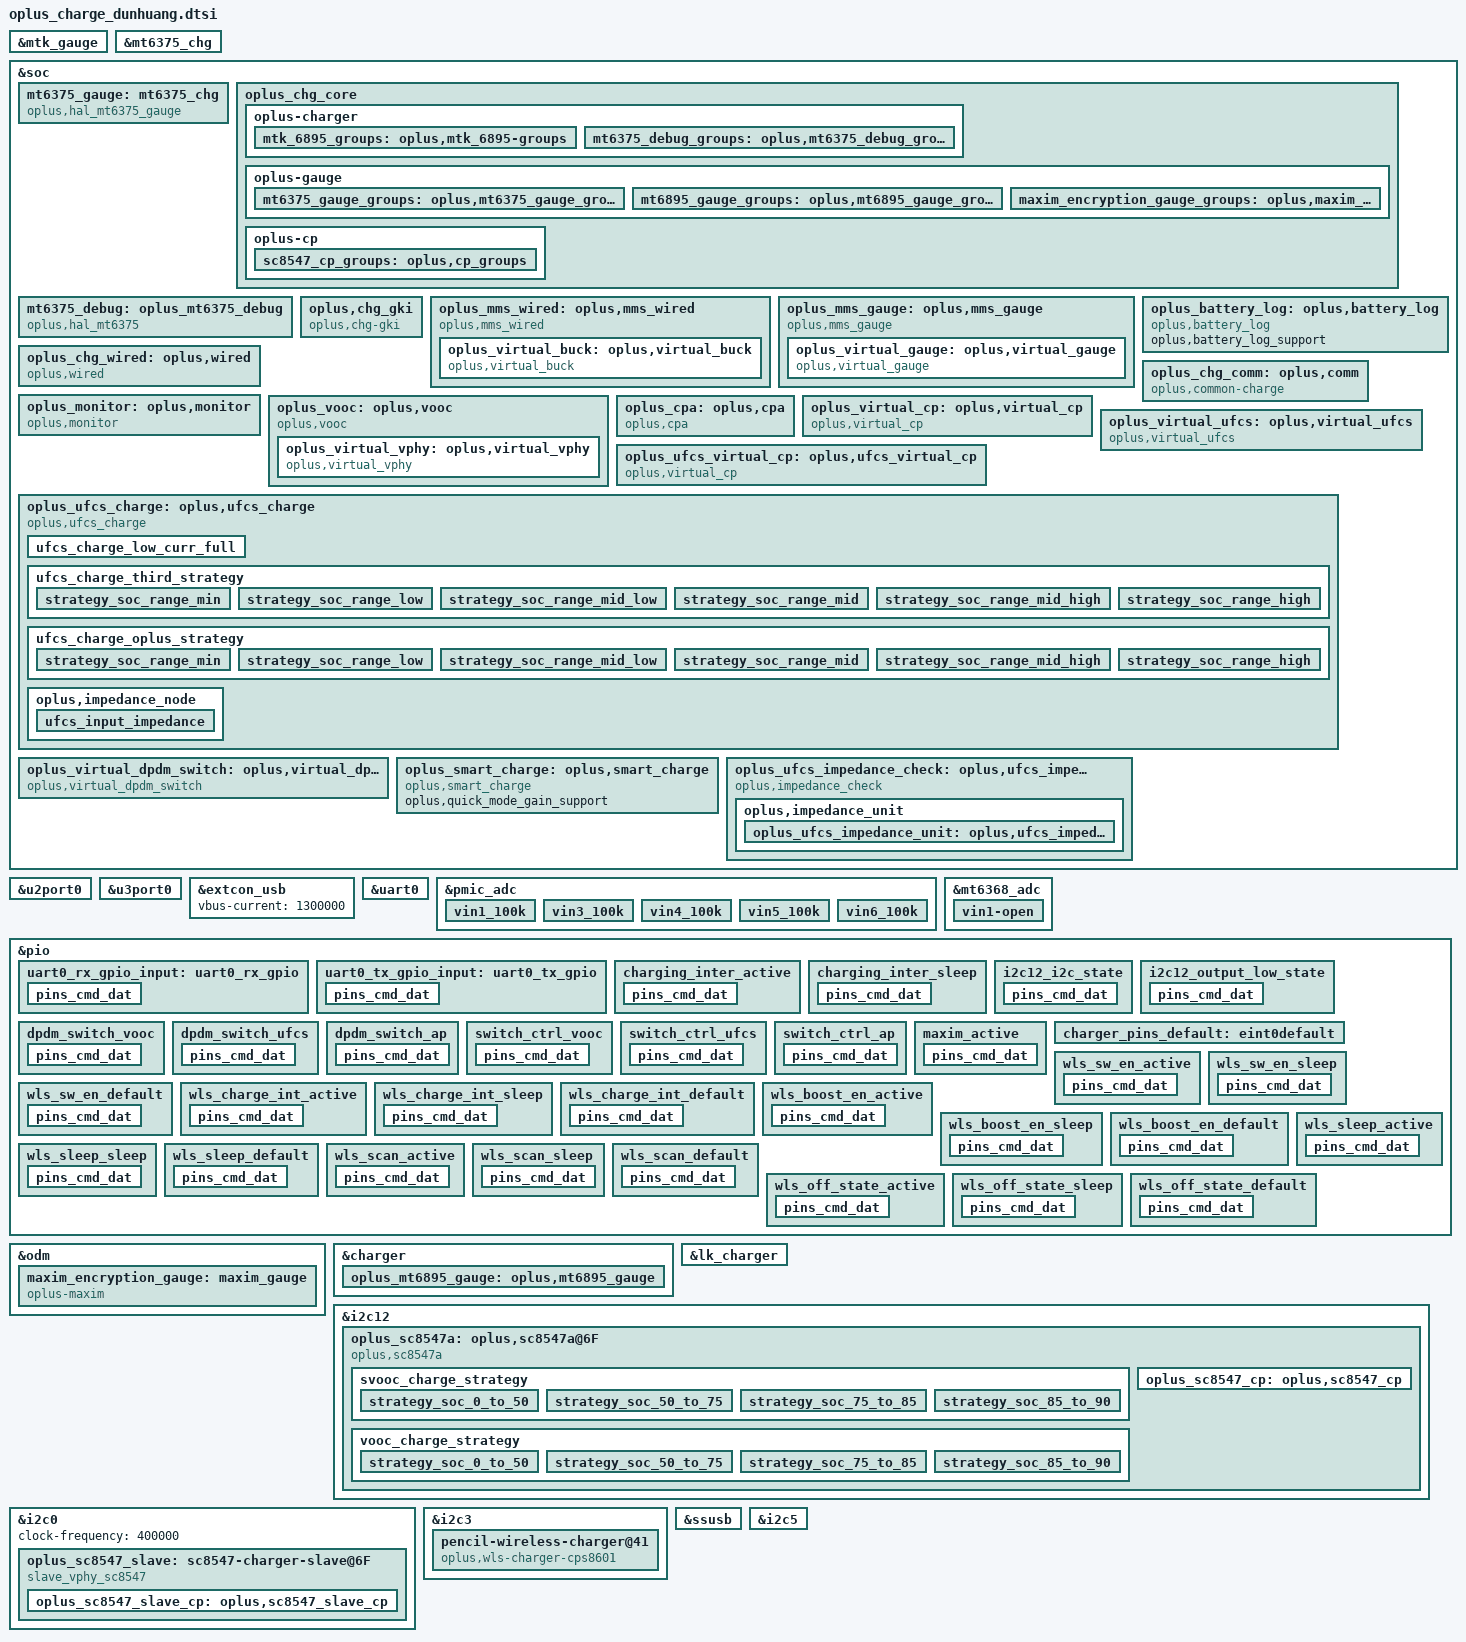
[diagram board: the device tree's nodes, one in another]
// SPDX-License-Identifier: GPL-2.0-only
/*
* Copyright (C) 2021-2020 Oplus. All rights reserved.
*/
#include <dt-bindings/iio/mt635x-auxadc.h>
#include <dt-bindings/iio/adc/mediatek,mt6375_auxadc.h>
#include <dt-bindings/pinctrl/mt6373-pinfunc.h>
#include <dt-bindings/pinctrl/mt65xx.h>
//#include "oplus_charge_22113.h"
#include "oplus_chg.h"

/*
 *
 * CPU:MT8792 dunhuang
 *
 * UTXD0 -->GPIO207
 * URXD0 -->GPIO208
 *
 * I2C
 * MASTER_CHG --> I2C5 MT6375
 * CP_MASTER  --> I2C12 SC8547B
 * CP_SLAVE   --> I2C0 SC8547B
 *
 * IRQB
 * EINT_CHG_1 (cp1 irq)               -->GPIO40
 * EINT_CHG_2 (cp2 irq)               -->GPIO61
 *
 * GPIO
 * VBUS_SHORT(防烧口)                 --> GPIO76
 * USB_SWITCH_1(usb/uart&vooc switch) --> GPIO115
 * USB_SWITCH_2(uart/vooc switch)     --> GPIO134
 * SEC_IC (加密电池GPIO for 80W)      --> GPIO23
 *
 * ADC:
 * MT6363 AUXADC_VIN6 				--> VBAT_BTB (Battery BTB)
 * MT6363 AUXADC_VIN1               --> NTC_USBCON_TEM (USB BTB)
 *
 * 
 * MT6368 AUXADC_VIN1				--> BATThermal_1 Ð¡°åNTC
 * MT6363 AUXADC_VIN3				--> ADC3 H10 //BB_USB_ADC1 防烧口NTC1
 * MT6363 AUXADC_VIN4				--> ADC4 G9//BB_USB_ADC2 防烧口NTC2
 * MT6363 AUXADC_VIN5				--> ADC5 H9//NTC_CHARGE (充电IC旁)
 *
 */

//&mtk_gauge {
//	disable-mtkbattery = <(1)>;
//	charger = <&mt6375_chg>;
//};

/* charge start */

&mtk_gauge {
	status = "okay";
	charger = <&mt6375_chg>;
	FUELGAGUE_APPLY = <(1)>;
	IS_SUBBOARD_TEMP_SUPPORT = <(0)>;
	EXTERNAL_AUTHENTICATE =<(1)>;
	Enable_Is_Force_Full = <(1)>;
	active-table = <(5)>;
	r-fg-value = <(2)>;/* R_sense resistance. 2 milliohm */
	com-r-fg-value = <(0)>;/* R_sense compensate resistance. not use COM_R_FG_VALUE */
	UNIT_MULTIPLE = <(1)>;
	RBAT_PULL_DOWN_R = <(24000)>;
	RBAT_PULL_UP_R = <(12000)>;
	RBAT_PULL_UP_VOLT = <(1840)>;
	USE_MORE_PRECISE_NTC_TABLE = <(1)>;
	car-tune-value = <(98)>;
	KEEP_100_PERCENT = <(0)>;
	temperature-t4 = <(-10)>;
	/* Battery temperature T4 */

	io-channels = <&mt6375_auxadc MT6375_AUXADC_BATSNS>,
				  <&mt6375_auxadc MT6375_AUXADC_BATON>,
				  <&mt6375_auxadc MT6375_AUXADC_IMP>,
				  <&mt6375_auxadc MT6375_AUXADC_IMIX_R>,
				  <&mt6375_auxadc MT6375_AUXADC_VREF>,
				  <&pmic_adc AUXADC_VIN2>;
	io-channel-names = "bat_volt", "bat_temp", "ptim_bat_volt",
					   "ptim_r", "vref", "auxadc5-batt_id_v";

	#include "bat_setting/mt6897_battery_prop_dim2_ext_dunhuang.dtsi"
	#include "bat_setting/mt6897_battery_table_dunhuang.dtsi"
};

&mt6375_chg {
	ircmp_v = <0>;
	chg-tmr = <20>;
};

&soc {
	mt6375_gauge: mt6375_chg {
		status = "okay";
		compatible = "oplus,hal_mt6375_gauge";

		oplus,ic_type = <OPLUS_CHG_IC_GAUGE>;
		oplus,ic_index = <0>;
		oplus,batt_num = <1>;
		oplus,mtk_gauge_power_sel_support;
	};
};

&u2port0 {
	mediatek,eye-vrt = <7>;
	mediatek,eye-term = <7>;
	mediatek,rev6 = <3>;
	mediatek,eye-vrt-host = <7>;
	mediatek,eye-term-host = <7>;
	mediatek,rev6-host = <3>;
	mediatek,discth = <0x9>;
};

&u3port0 {
	mediatek,tx-lctxc0 = <34>;
	mediatek,tx-lctxcp1 = <14>;
};

&extcon_usb {
	vbus-current = <1300000>;
};

&uart0 {
	pinctrl-names = "uart0_rx_gpio", "uart0_tx_gpio";
	pinctrl-0 = <&uart0_rx_gpio_input>;
	pinctrl-1 = <&uart0_tx_gpio_input>;
	status = "okay";

	txpin = <207>;
	rxpin = <208>;
};


/* pmic_adc is defined in mt6363.dtsi */
&pmic_adc {
	vin1_100k {
		channel = <AUXADC_VIN1>;
		pures = <ADC_PURES_100K>;
	};
	vin3_100k {
		channel = <AUXADC_VIN3>;
		pures = <ADC_PURES_100K>;
	};
	vin4_100k {
		channel = <AUXADC_VIN4>;
		pures = <ADC_PURES_100K>;
	};
	vin5_100k {
		channel = <AUXADC_VIN5>;
		pures = <ADC_PURES_100K>;
	};
	vin6_100k {
		channel = <AUXADC_VIN6>;
		pures = <ADC_PURES_100K>;
	};
};

/* mt6368_adc is defined in mt6368.dtsi */
&mt6368_adc {
	vin1-open {
		channel = <AUXADC_VIN1>;
		pures = <ADC_PURES_OPEN>;
	};
};

&pio {
	uart0_rx_gpio_input: uart0_rx_gpio {
		pins_cmd_dat {
			pinmux = <PINMUX_GPIO208__FUNC_GPIO208>; /* URXD0 */
			input-enable;
			bias-disable;
		};
	};

	uart0_tx_gpio_input: uart0_tx_gpio {
		pins_cmd_dat {
			pinmux = <PINMUX_GPIO207__FUNC_GPIO207>; /* UTXD0 */
			input-enable;
			bias-disable;
		};
	};

	charging_inter_active: charging_inter_active {
		pins_cmd_dat {
			pinmux = <PINMUX_GPIO40__FUNC_GPIO40>;
			input-enable;
			bias-pull-up;
		};
	};

	charging_inter_sleep: charging_inter_sleep {
		pins_cmd_dat {
			pinmux = <PINMUX_GPIO40__FUNC_GPIO40>;
			input-enable;
			bias-pull-up;
		};
	};

	i2c12_i2c_state: i2c12_i2c_state {
		pins_cmd_dat {
			pinmux = <PINMUX_GPIO162__FUNC_SDA12>,
				 <PINMUX_GPIO161__FUNC_SCL12>;
			bias-disable;
		};
	};

	i2c12_output_low_state: i2c12_output_low_state {
		pins_cmd_dat {
			pinmux = <PINMUX_GPIO162__FUNC_GPIO162>,
				 <PINMUX_GPIO161__FUNC_GPIO161>;
			output-low;
		};
	};

	dpdm_switch_vooc: dpdm_switch_vooc {
		pins_cmd_dat {
			pinmux = <PINMUX_GPIO115__FUNC_GPIO115>;
			output-high;
		};
 	};

 	dpdm_switch_ufcs: dpdm_switch_ufcs {
 		pins_cmd_dat {
			pinmux = <PINMUX_GPIO115__FUNC_GPIO115>;
			output-high;
		};
 	};

 	dpdm_switch_ap: dpdm_switch_ap {
 		pins_cmd_dat {
			pinmux = <PINMUX_GPIO115__FUNC_GPIO115>;
			output-low;
		};
 	};

 	switch_ctrl_vooc: switch_ctrl_vooc {
 		pins_cmd_dat {
			pinmux = <PINMUX_GPIO134__FUNC_GPIO134>;
			output-high;
		};
 	};

 	switch_ctrl_ufcs: switch_ctrl_ufcs {
 		pins_cmd_dat {
			pinmux = <PINMUX_GPIO134__FUNC_GPIO134>;
			output-high;
		};
 	};

 	switch_ctrl_ap: switch_ctrl_ap {
 		pins_cmd_dat {
			pinmux = <PINMUX_GPIO134__FUNC_GPIO134>;
			output-low;
		};
 	};

	maxim_active: maxim_active {
		pins_cmd_dat {
			pinmux = <PINMUX_GPIO23__FUNC_GPIO23>;
			drive-strength = <6>;
			bias-pull-up;
		};
	};

	charger_pins_default: eint0default {
	};

};


&soc {
	oplus_chg_core {
		oplus,chg_framework_v2;
		oplus,smart_charging_screenoff;
		oplus,common-charge-icl-support;

		oplus-charger {
			mtk_6895_groups: oplus,mtk_6895-groups {
				functions = <
					OPLUS_IC_FUNC_INIT
					OPLUS_IC_FUNC_EXIT
					OPLUS_IC_FUNC_REG_DUMP
					OPLUS_IC_FUNC_SMT_TEST
					OPLUS_IC_FUNC_BUCK_INPUT_PRESENT
					OPLUS_IC_FUNC_BUCK_INPUT_SUSPEND
					OPLUS_IC_FUNC_BUCK_INPUT_IS_SUSPEND
					OPLUS_IC_FUNC_BUCK_OUTPUT_SUSPEND
					OPLUS_IC_FUNC_BUCK_OUTPUT_IS_SUSPEND
					OPLUS_IC_FUNC_BUCK_SET_ICL
					OPLUS_IC_FUNC_BUCK_GET_ICL
					OPLUS_IC_FUNC_BUCK_SET_FCC
					OPLUS_IC_FUNC_BUCK_SET_FV
					OPLUS_IC_FUNC_BUCK_SET_ITERM
					OPLUS_IC_FUNC_BUCK_GET_INPUT_CURR
					OPLUS_IC_FUNC_BUCK_GET_INPUT_VOL
					OPLUS_IC_FUNC_OTG_BOOST_ENABLE
					OPLUS_IC_FUNC_BUCK_GET_CC_ORIENTATION
					OPLUS_IC_FUNC_BUCK_GET_CHARGER_TYPE
					OPLUS_IC_FUNC_BUCK_RERUN_BC12
					OPLUS_IC_FUNC_BUCK_QC_DETECT_ENABLE
					OPLUS_IC_FUNC_BUCK_SET_QC_CONFIG
					OPLUS_IC_FUNC_BUCK_SET_PD_CONFIG
					OPLUS_IC_FUNC_GET_SHUTDOWN_SOC
					OPLUS_IC_FUNC_BACKUP_SOC
					OPLUS_IC_FUNC_GET_TYPEC_MODE
					OPLUS_IC_FUNC_SET_TYPEC_MODE
					OPLUS_IC_FUNC_GET_TYPEC_ROLE
					OPLUS_IC_FUNC_GET_OTG_ENABLE
					OPLUS_IC_FUNC_BUCK_GET_HW_DETECT
					OPLUS_IC_FUNC_SET_USB_DISCHG_ENABLE
					OPLUS_IC_FUNC_GET_USB_DISCHG_STATUS
					OPLUS_IC_FUNC_IS_OPLUS_SVID
					OPLUS_IC_FUNC_BUCK_GET_USB_BTB_TEMP
					OPLUS_IC_FUNC_BUCK_GET_BATT_BTB_TEMP
					OPLUS_IC_FUNC_BUCK_SHIPMODE_ENABLE
					OPLUS_IC_FUNC_BUCK_SET_AICL_POINT
					OPLUS_IC_FUNC_SET_OTG_BOOST_CURR_LIMIT
					OPLUS_IC_FUNC_BUCK_GET_FV
					OPLUS_IC_FUNC_BUCK_GET_TYPEC_STATE
				>;
				virqs = <
					OPLUS_IC_VIRQ_ERR
					OPLUS_IC_VIRQ_CC_DETECT
					OPLUS_IC_VIRQ_PLUGIN
					OPLUS_IC_VIRQ_CC_CHANGED
					OPLUS_IC_VIRQ_CHG_TYPE_CHANGE
					OPLUS_IC_VIRQ_OTG_ENABLE
					OPLUS_IC_VIRQ_SVID
					OPLUS_IC_VIRQ_TYPEC_STATE
				>;
			};


			mt6375_debug_groups: oplus,mt6375_debug_groups {
				functions = <
					OPLUS_IC_FUNC_INIT
					OPLUS_IC_FUNC_EXIT
				>;
				virqs = <
					OPLUS_IC_VIRQ_ERR
				>;
			};
		};

		oplus-gauge {
			mt6375_gauge_groups: oplus,mt6375_gauge_groups {
				functions = <
					OPLUS_IC_FUNC_INIT
					OPLUS_IC_FUNC_EXIT
					OPLUS_IC_FUNC_REG_DUMP
					OPLUS_IC_FUNC_SMT_TEST
					OPLUS_IC_FUNC_GAUGE_GET_BATT_VOL
					OPLUS_IC_FUNC_GAUGE_GET_BATT_MAX
					OPLUS_IC_FUNC_GAUGE_GET_BATT_MIN
					OPLUS_IC_FUNC_GAUGE_GET_BATT_CURR
					OPLUS_IC_FUNC_GAUGE_GET_BATT_TEMP
					OPLUS_IC_FUNC_GAUGE_GET_BATT_SOC
					OPLUS_IC_FUNC_GAUGE_GET_BATT_FCC
					OPLUS_IC_FUNC_GAUGE_GET_BATT_CC
					OPLUS_IC_FUNC_GAUGE_GET_BATT_RM
					OPLUS_IC_FUNC_GAUGE_GET_BATT_SOH
					OPLUS_IC_FUNC_GAUGE_GET_BATT_HMAC
					OPLUS_IC_FUNC_GAUGE_SET_BATT_FULL
					OPLUS_IC_FUNC_GAUGE_UPDATE_DOD0
					OPLUS_IC_FUNC_GAUGE_UPDATE_SOC_SMOOTH
					OPLUS_IC_FUNC_GAUGE_GET_CB_STATUS
					OPLUS_IC_FUNC_GAUGE_GET_BATT_NUM
					OPLUS_IC_FUNC_GAUGE_GET_DEVICE_TYPE
					OPLUS_IC_FUNC_GAUGE_GET_DEVICE_TYPE_FOR_VOOC
					OPLUS_IC_FUNC_GAUGE_GET_BATT_FCC
					OPLUS_IC_FUNC_GAUGE_GET_BATT_FC
					OPLUS_IC_FUNC_GAUGE_GET_BATT_QM
					OPLUS_IC_FUNC_GAUGE_GET_BATT_PD
					OPLUS_IC_FUNC_GAUGE_GET_BATT_RCU
					OPLUS_IC_FUNC_GAUGE_GET_BATT_RCF
					OPLUS_IC_FUNC_GAUGE_GET_BATT_FCU
					OPLUS_IC_FUNC_GAUGE_GET_BATT_FCF
					OPLUS_IC_FUNC_GAUGE_GET_BATT_SOU
					OPLUS_IC_FUNC_GAUGE_GET_BATT_DO0
					OPLUS_IC_FUNC_GAUGE_GET_BATT_DOE
					OPLUS_IC_FUNC_GAUGE_GET_BATT_TRM
					OPLUS_IC_FUNC_GAUGE_GET_BATT_PC
					OPLUS_IC_FUNC_GAUGE_GET_BATT_QS
					OPLUS_IC_FUNC_GAUGE_IS_SUSPEND
					OPLUS_IC_FUNC_GAUGE_GET_BCC_PARMS
					OPLUS_IC_FUNC_GAUGE_FASTCHG_UPDATE_BCC_PARMS
					OPLUS_IC_FUNC_GAUGE_GET_PREV_BCC_PARMS
					OPLUS_IC_FUNC_GAUGE_SET_BCC_PARMS
					OPLUS_IC_FUNC_GAUGE_SET_PROTECT_CHECK
					OPLUS_IC_FUNC_GAUGE_GET_AFI_UPDATE_DONE
					OPLUS_IC_FUNC_GAUGE_CHECK_RESET
					OPLUS_IC_FUNC_GAUGE_GET_DEVICE_TYPE_FOR_BCC
					OPLUS_IC_FUNC_GAUGE_GET_DOD0
					OPLUS_IC_FUNC_GAUGE_GET_DOD0_PASSED_Q
					OPLUS_IC_FUNC_GAUGE_GET_QMAX
					OPLUS_IC_FUNC_GAUGE_GET_QMAX_PASSED_Q
					OPLUS_IC_FUNC_GAUGE_SET_BATTERY_CURVE
				>;
				virqs = <
					OPLUS_IC_VIRQ_ERR
					OPLUS_IC_VIRQ_OFFLINE
					OPLUS_IC_VIRQ_RESUME
				>;
			};

			mt6895_gauge_groups: oplus,mt6895_gauge_groups {
				functions = <
					OPLUS_IC_FUNC_INIT
					OPLUS_IC_FUNC_EXIT
					OPLUS_IC_FUNC_GAUGE_GET_SUBBOARD_TEMP
				>;
				virqs = <
					OPLUS_IC_VIRQ_ERR
				>;
			};

			maxim_encryption_gauge_groups: oplus,maxim_encryption_gauge_groups {
				functions = <
					OPLUS_IC_FUNC_INIT
					OPLUS_IC_FUNC_EXIT
					OPLUS_IC_FUNC_GAUGE_GET_BATT_AUTH
				>;
				virqs = <
					OPLUS_IC_VIRQ_ERR
				>;
			};
		};
		oplus-cp {
			sc8547_cp_groups: oplus,cp_groups {
			functions = <
					OPLUS_IC_FUNC_INIT
					OPLUS_IC_FUNC_EXIT
					OPLUS_IC_FUNC_REG_DUMP
					OPLUS_IC_FUNC_SMT_TEST
					OPLUS_IC_FUNC_CP_ENABLE
					OPLUS_IC_FUNC_CP_HW_INTI
					OPLUS_IC_FUNC_CP_SET_WORK_START
					OPLUS_IC_FUNC_CP_CHECK_WORK_MODE_SUPPORT
					OPLUS_IC_FUNC_CP_SET_WORK_MODE
					OPLUS_IC_FUNC_CP_GET_WORK_MODE
					OPLUS_IC_FUNC_CP_GET_VIN
					OPLUS_IC_FUNC_CP_GET_IIN
					OPLUS_IC_FUNC_CP_SET_IIN
					OPLUS_IC_FUNC_CP_GET_VOUT
					OPLUS_IC_FUNC_CP_GET_IOUT
					OPLUS_IC_FUNC_CP_GET_VAC
					OPLUS_IC_FUNC_CP_GET_WORK_STATUS
					OPLUS_IC_FUNC_CP_SET_ADC_ENABLE
					OPLUS_IC_FUNC_CP_WATCHDOG_ENABLE
				>;
				virqs = <
					OPLUS_IC_VIRQ_ERR
					OPLUS_IC_VIRQ_ONLINE
					OPLUS_IC_VIRQ_OFFLINE
				>;
			};
		};
	};
};

&soc {
	mt6375_debug: oplus_mt6375_debug {
		status = "okay";
		compatible = "oplus,hal_mt6375";

		oplus,tcpc_name = "type_c_port0";

		oplus,ic_type = <OPLUS_CHG_IC_BUCK>;
		oplus,ic_index = <2>;
	};
};

&odm {
	maxim_encryption_gauge: maxim_gauge {
		status = "okay";
		compatible = "oplus-maxim";
		pinctrl-names = "maxim_active";
		pinctrl-0 = <&maxim_active>;
		support_encryption_in_lk;
		data-gpio = <&pio 23 0x00>;
		gpio-addr-set-out = <0x10005004>;
		gpio-addr-set-in = <0x10005008>;
		gpio-addr-level_high = <0x10005104>;
		gpio-addr-level_low = <0x10005108>;
		gpio-addr-data-in = <0x10005200>;
		gpio-addr-offset = <0x23>;
		oplus,batt_info = /bits/ 8 <0x36 0x31 0x31 0x33 0x30 0x37 0x30 0x30 0x30 0x30 0x34 0x32
					0x36 0x31 0x31 0x33 0x30 0x37 0x30 0x30 0x30 0x30 0x33 0x30
					0x36 0x31 0x31 0x33 0x30 0x37 0x30 0x30 0x30 0x30 0x33 0x31>;
		oplus,ic_type = <OPLUS_CHG_IC_GAUGE>;
		oplus,ic_index = <2>;
	};
};

&soc {
	oplus,chg_gki {
		compatible = "oplus,chg-gki";
	};
};

&charger {
	io-channels = <&pmic_adc (ADC_PURES_100K_MASK | AUXADC_VIN5)>,
			<&mt6368_adc (ADC_PURES_100K_MASK | AUXADC_VIN1)>,
			<&pmic_adc (ADC_PURES_100K_MASK | AUXADC_VIN6)>,
			<&pmic_adc (ADC_PURES_100K_MASK | AUXADC_VIN1)>;
	io-channel-names = "auxadc5-chargeric_temp", "auxadc1-ntc_sub_bat_tem",
			   "auxadc5_batt_btb_temp", "auxadc6_usb_btb_temp";

	pinctrl-names = "default";
	pinctrl-0 = <&charger_pins_default>;
	oplus,support_ntc_01c_precision;
	oplus,support_subboard_ntc;
	max_charger_voltage = <15000000>;
	oplus,ntc_temp_volt_1840mv;
	oplus,force_use_4250K_ntc;

	/* usbtemp dischg use pmic regulator to set vbus down */
	oplus,support_usbtemp_dischg_reg_configurable;
	oplus,usbtemp_dischg_reg_addr = <0x989>;
	oplus,usbtemp_dischg_reg_mask = <0x7>;
	oplus,usbtemp_dischg_enable = <0x2>;
	oplus,usbtemp_dischg_disable = <0x0>;

	oplus,ic_type = <OPLUS_CHG_IC_BUCK>;
	oplus,ic_index = <0>;

	oplus_mt6895_gauge: oplus,mt6895_gauge {
		oplus,ic_type = <OPLUS_CHG_IC_GAUGE>;
		oplus,ic_index = <1>;
	};
};

&lk_charger {
	en_vol_ctrl_vibrate = <3200>;
	support_tuv_authentication;
	charger_no_wiress;
	support_battery_type = <2>;
	support_maxim_battery_authentication;
	data-gpio = <23>;
	oplus,batt_info = /bits/ 8 <0x36 0x31 0x31 0x33 0x30 0x37 0x30 0x30 0x30 0x30 0x34 0x32
				0x36 0x31 0x31 0x33 0x30 0x37 0x30 0x30 0x30 0x30 0x33 0x30
				0x36 0x31 0x31 0x33 0x30 0x37 0x30 0x30 0x30 0x30 0x33 0x31>;
	support_sdp_screenoff;
	sdp_screenon_voltage = <3000>;
	support_quickboot_charge;
	high-temp-scheme;
	over_high_temp_thr = <60>;
	sub_board_temp_support;
	sub_board_adc_channel = <18>;
	sub_board_adc_pmic = <1>;
	sub_board_adc_pull_up_voltage = <1840>;
	sub_board_adc_pures = <0>;
	support_panel_suspend;
	support_sdp_backlight;
	max-charger-voltage = <15000000>;
	boot-battery-voltage = <3350000>;
	usb-charger-current = <500000>;
	ac-charger-current = <2050000>;
	ac-charger-input-current = <1500000>;
	non-std-ac-charger-current = <750000>;
	charging-host-charger-current = <1500000>;
	ta-ac-charger-current = <1500000>;
	pd-charger-current = <500000>;
};


&soc {
	oplus_mms_wired: oplus,mms_wired {
		compatible = "oplus,mms_wired";
		oplus,buck_ic = <&oplus_virtual_buck>;
		oplus,voocphy_ic = <&oplus_virtual_vphy>;
		oplus,adc_info_name = "100k_1840mv";
		oplus_spec,usbtemp_batttemp_gap = <12>;

		/* support for V2.0 usbtemp protect. */
		oplus,support_usbtemp_protect_v2;
		oplus_spec,usbtemp_batt_temp_low = <50>;
		oplus_spec,usbtemp_batt_temp_high = <50>;
		oplus_spec,usbtemp_batt_temp_over_hot = <60>;
		oplus_spec,usbtemp_ntc_temp_low = <57>;
		oplus_spec,usbtemp_ntc_temp_high = <69>;
		oplus_spec,usbtemp_temp_gap_low_with_batt_temp = <7>;
		oplus_spec,usbtemp_temp_gap_with_batt_temp_in_over_hot = <15>;
		oplus_spec,usbtemp_temp_gap_high_with_batt_temp = <12>;
		oplus_spec,usbtemp_temp_gap_low_without_batt_temp = <12>;
		oplus_spec,usbtemp_temp_gap_high_without_batt_temp = <24>;
		oplus_spec.usbtemp_rise_fast_temp_low = <3>;
		oplus_spec.usbtemp_rise_fast_temp_high = <3>;
		oplus_spec.usbtemp_rise_fast_temp_count_low = <30>;
		oplus_spec.usbtemp_rise_fast_temp_count_high = <20>;
		oplus_spec,usbtemp_cool_down_ntc_low = <54>;
		oplus_spec,usbtemp_cool_down_ntc_high = <65>;
		oplus_spec,usbtemp_cool_down_gap_low = <12>;
		oplus_spec,usbtemp_cool_down_gap_high = <20>;
		oplus_spec,usbtemp_cool_down_recover_ntc_low = <48>;
		oplus_spec,usbtemp_cool_down_recover_ntc_high = <60>;
		oplus_spec,usbtemp_cool_down_recover_gap_low = <6>;
		oplus_spec,usbtemp_cool_down_recover_gap_high = <15>;

		oplus_virtual_buck: oplus,virtual_buck {
			compatible = "oplus,virtual_buck";
			oplus,buck_ic = <&charger &mt6375_debug>;
			oplus,buck_ic_index = <0 1>;
			oplus,buck_ic_current_ratio = <100 0>;
			oplus,buck_ic_connect = <OPLUS_CHG_IC_CONNECT_PARALLEL>;
			oplus,main_charger = <0>;
			oplus,buck_ic_func_group = <&mtk_6895_groups &mt6375_debug_groups>;

			oplus,ic_type = <OPLUS_CHG_IC_VIRTUAL_BUCK>;
			oplus,ic_index = <0>;

			io-channels = <&pmic_adc AUXADC_VIN3>, <&pmic_adc AUXADC_VIN4>;
			io-channel-names = "usb_temp_adc_l", "usb_temp_adc_r";

			oplus,uart_tx-gpio = <&pio 207 0x00>;
			oplus,uart_rx-gpio = <&pio 208 0x00>;
		};
	};

	oplus_mms_gauge: oplus,mms_gauge {
		compatible = "oplus,mms_gauge";
		oplus,gauge_ic = <&oplus_virtual_gauge>;
		oplus,voocphy_ic = <&oplus_virtual_vphy>;
		oplus,topic-update-interval = <10000>;
		oplus,support_subboard_ntc;

		oplus_virtual_gauge: oplus,virtual_gauge {
			compatible = "oplus,virtual_gauge";
			oplus,gauge_ic = <&mt6375_gauge &oplus_mt6895_gauge &maxim_encryption_gauge>;
			oplus,gauge_ic_index = <0 1 2>;
			oplus,gauge_ic_func_group = <&mt6375_gauge_groups &mt6895_gauge_groups &maxim_encryption_gauge_groups>;
			oplus,batt_capacity_mah = <9230>;
			oplus,ic_type = <OPLUS_CHG_IC_VIRTUAL_GAUGE>;
			oplus,ic_index = <0>;
		};
	};
};

&soc {
	oplus_battery_log: oplus,battery_log {
		compatible = "oplus,battery_log";
		oplus,battery_log_support;
	};

	oplus_chg_wired: oplus,wired {
		compatible = "oplus,wired";

		oplus,vooc-support;

		oplus_spec,vbatt_pdqc_to_5v_thr = <4100>;
		oplus_spec,vbatt_pdqc_to_9v_thr = <5000>;
		oplus_spec,pd-iclmax-ma = <2000>;
		oplus_spec,qc-iclmax-ma = <2000>;
		oplus_spec,non-standard-ibatmax-ma = <500>;
		oplus_spec,input-power-mw = <
			500		/* OPLUS_WIRED_CHG_MODE_UNKNOWN */
			2500		/* OPLUS_WIRED_CHG_MODE_SDP */
			7500		/* OPLUS_WIRED_CHG_MODE_CDP */
			10000		/* OPLUS_WIRED_CHG_MODE_DCP */
			15000		/* OPLUS_WIRED_CHG_MODE_VOOC */
			13500		/* OPLUS_WIRED_CHG_MODE_QC */
			13500		/* OPLUS_WIRED_CHG_MODE_PD */
		>;
		oplus_spec,led_on-fccmax-ma = <0 1140 4000 4000 4000 4000 1000 0>;
		oplus_spec,fccmax-ma-lv = <
			0 1200 2200 2200 2200 2200 2200 0	/* OPLUS_WIRED_CHG_MODE_UNKNOWN */
			0 600  600  600  600  600  600  0	/* OPLUS_WIRED_CHG_MODE_SDP */
			0 1200 1600 1600 1600 1600 1600 0	/* OPLUS_WIRED_CHG_MODE_CDP */
			0 1200 2200 2200 2200 2200 2200 0	/* OPLUS_WIRED_CHG_MODE_DCP */
			0 1200 3600 3600 3600 3600 2200 0	/* OPLUS_WIRED_CHG_MODE_VOOC */
			0 1200 4000 4000 4000 4000 2200 0	/* OPLUS_WIRED_CHG_MODE_QC */
			0 1200 4000 4000 4000 4000 2200 0	/* OPLUS_WIRED_CHG_MODE_PD */
		>;
		oplus_spec,fccmax-ma-hv = <
			0 1200 2200 2200 2200 2200 2200 0	/* OPLUS_WIRED_CHG_MODE_UNKNOWN */
			0 600  600  600  600  600  600  0	/* OPLUS_WIRED_CHG_MODE_SDP */
			0 1200 1600 1600 1600 1600 1600 0	/* OPLUS_WIRED_CHG_MODE_CDP */
			0 1200 2200 2200 2200 2200 2200 0	/* OPLUS_WIRED_CHG_MODE_DCP */
			0 1200 3600 3600 3600 3600 2200 0	/* OPLUS_WIRED_CHG_MODE_VOOC */
			0 1200 4000 4000 4000 4000 2200 0	/* OPLUS_WIRED_CHG_MODE_QC */
			0 1200 4000 4000 4000 4000 2200 0	/* OPLUS_WIRED_CHG_MODE_PD */
		>;

		oplus_spec,cool_down_pdqc_vol_mv = <9000 9000 9000>;
		oplus_spec,cool_down_pdqc_curr_ma = <1200 1500 2000>;
		oplus_spec,cool_down_vooc_curr_ma = <1200 1500 2000 2500 3000 3000>;
		oplus_spec,cool_down_normal_curr_ma = <1200 1500 2000>;

		oplus_spec,vbus_ov_thr_mv = <10200 10200>;
		oplus_spec,vbus_uv_thr_mv = <4300 4300>;

		/* first data is strategy used temp type */
		oplus,vooc_strategy_name = "cgcl";
		oplus,vooc_strategy_data = <OPLUS_STRATEGY_USE_BATT_TEMP
					    0   350 3000 1 0
					    330 370 3000 2 0
					    350 440 2200 2 1>;
	};

	oplus_chg_comm: oplus,comm {
		compatible = "oplus,common-charge";
		oplus_spec,batt-them-thr = <(-100) 0 50 120 160 450 530>;
		oplus_spec,iterm-ma = <500>; /* 9510*0.05+10 */
		oplus_spec,removed_bat_decidegc = <390>; /*-39 degree*/
		oplus_spec,fv-mv = <0 4440 4465 4465 4465 4465 4130 4130>;
		oplus_spec,sw-fv-mv = <0 4410 4420 4420 4420 4420 4080 4080>;
		oplus_spec,hw-fv-inc-mv = <0 18 18 18 18 18 18 0>;
		oplus_spec,sw-over-fv-mv = <0 4440 4475 4475 4475 4475 4140 4140>;
		oplus_spec,sw-over-fv-dec-mv = <8>;
		oplus_spec,non-standard-sw-fv-mv = <3930>;
		oplus_spec,non-standard-fv-mv = <3980>;
		oplus_spec,non-standard-hw-fv-inc-mv = <18>;
		oplus_spec,non-standard-sw-over-fv-mv = <3990>;
		oplus_spec,non-standard-vbatdet-mv = <3600>;
		oplus_spec,wired-vbatdet-mv = <0 4130 4265 4365 4365 4365 4030 0>;
		oplus_spec,fcc-gear-thr-mv = <4180>;
		oplus_spec,vbatt-ov-thr-mv = <4600>;

		oplus_spec,full_pre_ffc_judge;
		oplus_spec,full-pre-ffc-mv = <4435>;
		oplus_spec,ffc-temp-thr = <160 350 400>;
		oplus_spec,wired-ffc-step-max = <2>;
		oplus_spec,wired-ffc-fv-mv = <4550 4550>;

		oplus_spec,wired-ffc-fv-cutoff-mv = <4485 4485 4485 4485>;
		oplus_spec,wired-ffc-fcc-ma = <1600 1700
					       1600 1700>;
		oplus_spec,wired-ffc-fcc-cutoff-ma = <1400 1500
						      1400 1500>;
		oplus_spec,vbat_uv_thr_mv = <3300>;
		oplus_spec,vbat_charging_uv_thr_mv = <3200>;

		/*If use subboard NTC as battery temp, config it as 20, otherwise 0 */
		oplus_spec,tbatt_power_off_cali_temp = <0>;
		oplus_spec,poweroff_high_batt_temp = <720>;
		oplus_spec,poweroff_emergency_batt_temp = <770>;
		oplus,vooc_show_ui_soc_decimal;
		oplus,ui_soc_decimal_speedmin = <20>;
		oplus,gauge_stuck_jump_support;
		oplus,gauge_stuck_threshold = <15>;
		oplus,gauge_stuck_time = <50>;
	};

	oplus_monitor: oplus,monitor {
		compatible = "oplus,monitor";
		oplus,topic-update-interval = <60000>;

		track,fast_chg_break_t_thd = <1000>;
		track,general_chg_break_t_thd = <200>;
		track,voocphy_type = <TRACK_AP_DUAL_CP_VOOCPHY>;
		track,wired_max_power = <67000>;
		track,wired_fast_chg_scheme = <2>;
	};

	oplus_vooc: oplus,vooc {
		compatible = "oplus,vooc";
		oplus,vooc_ic = <&oplus_virtual_vphy>;

		oplus_spec,vooc_soc_range = <50 75 85>;
		oplus_spec,vooc_temp_range = <50 120 180 350 450>;

		oplus,vooc_data_width = <7>;
		oplus,vooc_curr_max = <CP_CURR_LIMIT_7BIT_12_6A>; /* 67W: 11V 6.1A(IBUS *2) */
		oplus,vooc_power_max_w = <67>;
		oplus,vooc_project = <13>;
		oplus,vooc_curr_table_type = <VOOC_CP_CURR_TABLE>;
		oplus,voocphy_support = <3>; /* AP_DUAL_CP_VOOCPHY */
		oplus,support_fake_vooc_check;
		oplus,subboard_ntc_abnormal_current = <4000>;

		oplus,abnormal_adapter_current = <CP_CURR_LIMIT_7BIT_12_6A CP_CURR_LIMIT_7BIT_12_6A
						CP_CURR_LIMIT_7BIT_10_0A CP_CURR_LIMIT_7BIT_10_0A
						CP_CURR_LIMIT_7BIT_8_0A CP_CURR_LIMIT_7BIT_8_0A
						CP_CURR_LIMIT_7BIT_6_0A CP_CURR_LIMIT_7BIT_6_0A
						CP_CURR_LIMIT_7BIT_4_0A CP_CURR_LIMIT_7BIT_4_0A>;

		/* first data is strategy used temp type */
		oplus,general_strategy_name = "cgcl";
		oplus,general_strategy_data = < OPLUS_STRATEGY_USE_SHELL_TEMP
						0   385 CP_CURR_LIMIT_7BIT_12_6A 1 0
						389 395 CP_CURR_LIMIT_7BIT_10_0A 2 0
						398 420 CP_CURR_LIMIT_7BIT_8_0A 3 1
						405 440 CP_CURR_LIMIT_7BIT_6_0A 3 2 >;


		oplus_virtual_vphy: oplus,virtual_vphy {
			compatible = "oplus,virtual_vphy";
			oplus,vphy_ic = <&oplus_sc8547a>;

			oplus,ic_type = <OPLUS_CHG_IC_VIRTUAL_VPHY>;
			oplus,ic_index = <0>;
			oplus,dpdm_switch_ic = <&oplus_virtual_dpdm_switch>;
		};
	};

	oplus_cpa: oplus,cpa {
		compatible = "oplus,cpa";
		oplus,protocol_list = <CHG_PROTOCOL_PD 18
				       CHG_PROTOCOL_VOOC 67
				       CHG_PROTOCOL_QC 18>;
		oplus,default_protocol_list = <CHG_PROTOCOL_PD
					       CHG_PROTOCOL_VOOC>;
	};

	oplus_virtual_cp: oplus,virtual_cp {
		compatible = "oplus,virtual_cp";

		oplus,ic_type = <OPLUS_CHG_IC_VIRTUAL_CP>;
		oplus,ic_index = <0>;

		oplus,cp_ic = <&oplus_sc8547_cp &oplus_sc8547_slave_cp>;
		oplus,input_curr_max_ma = <3000 3000>;

		oplus,cp_ic_connect = <OPLUS_CHG_IC_CONNECT_PARALLEL>;
		oplus,main_cp = <0>;

		oplus,reg_proc_node;
	};

	oplus_ufcs_virtual_cp: oplus,ufcs_virtual_cp {
		compatible = "oplus,virtual_cp";

		oplus,ic_type = <OPLUS_CHG_IC_VIRTUAL_CP>;
		oplus,ic_index = <1>;

		oplus,cp_ic = <&oplus_virtual_cp>;
		oplus,input_curr_max_ma = <3000>;

		oplus,cp_ic_connect = <OPLUS_CHG_IC_CONNECT_PARALLEL>;
		oplus,main_cp = <0>;
	};

	oplus_virtual_ufcs: oplus,virtual_ufcs {
		compatible = "oplus,virtual_ufcs";

		oplus,ic_type = <OPLUS_CHG_IC_VIRTUAL_UFCS>;
		oplus,ic_index = <0>;
	};

	oplus_ufcs_charge: oplus,ufcs_charge {
		compatible = "oplus,ufcs_charge";
		oplus,ufcs_ic = <&oplus_virtual_ufcs>;
		oplus,cp_ic = <&oplus_virtual_cp>;
		oplus,dpdm_switch_ic = <&oplus_virtual_dpdm_switch>;

		oplus,impedance_unit = <&oplus_ufcs_impedance_unit>;

		oplus,target_vbus_mv = <11000>;
		oplus,curr_max_ma = <3000>;

		oplus,curr_table_type = <UFCS_CURR_CP_TABLE>;
		oplus,high_imp_compensation_setting_mv = <50>;

		oplus,ufcs_warm_allow_vol = <4000>;
		oplus,ufcs_warm_allow_soc = <50>;
		oplus,ufcs_strategy_normal_current = <3000>;//6A
		oplus,ufcs_over_high_or_low_current = <3000>;
		oplus,ufcs_timeout_third = <23734>;
		oplus,ufcs_timeout_oplus = <23734>;
		oplus,ufcs_ibat_over_third = <7000>;
		oplus,ufcs_ibat_over_oplus = <7000>;
		oplus,ufcs_full_cool_sw_vbat = <4480>;
		oplus,ufcs_full_normal_sw_vbat = <4500>;
		oplus,ufcs_full_normal_hw_vbat = <4510>;
		oplus,ufcs_full_ffc_vbat = <4520>;
		oplus,ufcs_full_warm_vbat = <4130>;
		oplus,ufcs_full_cool_sw_vbat_third = <4470>;
		oplus,ufcs_full_normal_sw_vbat_third= <4470>;
		oplus,ufcs_full_normal_hw_vbat_third = <4480>;
		oplus,ufcs_current_change_timeout = <100>;
		oplus,ufcs_strategy_batt_high_temp = <410 420 430 400 410 420>;
		oplus,ufcs_strategy_high_current = <2000 2000 2000 3000 3000 3000>;
		oplus,ufcs_charge_strategy_soc = <0 20 35 50 75 85 90>;
		oplus,ufcs_charge_strategy_temp = <0 50 120 200 350 440 530>;
		oplus,ufcs_low_curr_full_strategy_temp = <0 200 350 440>;

		ufcs_charge_low_curr_full {
			strategy_temp_little_cool = 	<1500 4490 0
							 1400 4480 0
							 1300 4470 0
							 1200 4460 0
							 1100  4450 1>;
			strategy_temp_normal_low =	<1500 4490 0
                                                         1400 4480 0
                                                         1300 4470 0
                                                         1200 4460 0
                                                         1100  4450 1>;
			strategy_temp_normal_high = 	<1600 4490 0
                                                         1400 4480 0
                                                         1300 4470 0
                                                         1200 4460 0
                                                         1100  4450 1>;
		};

		ufcs_charge_third_strategy {
			oplus,temp_type = <OPLUS_STRATEGY_USE_SHELL_TEMP>;
			oplus,soc_range = <0 20 35 50 75 85 90>;
			oplus,temp_range = <0 50 120 160 350 440 530>;

			strategy_soc_range_min { /* ui_soc: 0%~20% */
				strategy_temp_little_cold =	<11000 4455 2500 0 0
								11000 4455 2000 0 0
								11000 4455 1500 0 0
								11000 4465 1000 1 0>;
				strategy_temp_cool =		<11000 4455 3000 0 0
								11000 4455 2500 0 0
								11000 4455 2000 0 0
								11000 4455 1500 0 0
								11000 4465 1000 1 0>;
				strategy_temp_little_cool =	<11000 4460 3000 0 0
								11000 4460 2500 0 0
								11000 4460 2000 0 0
								11000 4460 1500 0 0
								11000 4470 1000 1 0>;
				strategy_temp_normal_low =	<11000 4460 3000 0 0
								11000 4460 2500 0 0
								11000 4460 2000 0 0
								11000 4460 1500 0 0
								11000 4470 1000 1 0>;
				strategy_temp_normal_high =	<11000 4460 3000 0 0
								11000 4460 2500 0 0
								11000 4460 2000 0 0
								11000 4460 1500 0 0
								11000 4470 1000 1 0>;
				strategy_temp_warm =		<11000 4130 1000 1 0>;
			};
			strategy_soc_range_low { /* ui_soc: 21%~35% */
				strategy_temp_little_cold =	<11000 4455 2500 0 0
								11000 4455 2000 0 0
								11000 4455 1500 0 0
								11000 4465 1000 1 0>;
				strategy_temp_cool =		<11000 4455 3000 0 0
								11000 4455 2500 0 0
								11000 4455 2000 0 0
								11000 4455 1500 0 0
								11000 4465 1000 1 0>;
				strategy_temp_little_cool =	<11000 4460 3000 0 0
								11000 4460 2500 0 0
								11000 4460 2000 0 0
								11000 4460 1500 0 0
								11000 4470 1000 1 0>;
				strategy_temp_normal_low =	<11000 4460 3000 0 0
								11000 4460 2500 0 0
								11000 4460 2000 0 0
								11000 4460 1500 0 0
								11000 4470 1000 1 0>;
				strategy_temp_normal_high =	<11000 4460 3000 0 0
								11000 4460 2500 0 0
								11000 4460 2000 0 0
								11000 4460 1500 0 0
								11000 4470 1000 1 0>;
				strategy_temp_warm =		<11000 4130 1000 1 0>;
			};
			strategy_soc_range_mid_low { /* ui_soc: 36%~50% */
				strategy_temp_little_cold =	<11000 4455 2500 0 0
								11000 4455 2000 0 0
								11000 4455 1500 0 0
								11000 4465 1000 1 0>;
				strategy_temp_cool =		<11000 4455 3000 0 0
								11000 4455 2500 0 0
								11000 4455 2000 0 0
								11000 4455 1500 0 0
								11000 4465 1000 1 0>;
				strategy_temp_little_cool =	<11000 4460 3000 0 0
								11000 4460 2500 0 0
								11000 4460 2000 0 0
								11000 4460 1500 0 0
								11000 4470 1000 1 0>;
				strategy_temp_normal_low =	<11000 4460 3000 0 0
								11000 4460 2500 0 0
								11000 4460 2000 0 0
								11000 4460 1500 0 0
								11000 4470 1000 1 0>;
				strategy_temp_normal_high =	<11000 4460 3000 0 0
								11000 4460 2500 0 0
								11000 4460 2000 0 0
								11000 4460 1500 0 0
								11000 4470 1000 1 0>;
				strategy_temp_warm =		<11000 4130 1000 1 0>;
			};
			strategy_soc_range_mid { /* ui_soc: 51%~75% */
				strategy_temp_little_cold =	<11000 4455 2500 0 0
								11000 4455 2000 0 0
								11000 4455 1500 0 0
								11000 4465 1000 1 0>;
				strategy_temp_cool =		<11000 4455 3000 0 0
								11000 4455 2500 0 0
								11000 4455 2000 0 0
								11000 4455 1500 0 0
								11000 4465 1000 1 0>;
				strategy_temp_little_cool =	<11000 4460 3000 0 0
								11000 4460 2500 0 0
								11000 4460 2000 0 0
								11000 4460 1500 0 0
								11000 4470 1000 1 0>;
				strategy_temp_normal_low =	<11000 4460 3000 0 0
								11000 4460 2500 0 0
								11000 4460 2000 0 0
								11000 4460 1500 0 0
								11000 4470 1000 1 0>;
				strategy_temp_normal_high =	<11000 4460 3000 0 0
								11000 4460 2500 0 0
								11000 4460 2000 0 0
								11000 4460 1500 0 0
								11000 4470 1000 1 0>;
				strategy_temp_warm =		<11000 4130 1000 1 0>;
			};
			strategy_soc_range_mid_high { /* ui_soc: 76%~85% */
				strategy_temp_little_cold =	<11000 4455 2000 0 0
								11000 4455 1500 0 0
								11000 4465 1000 1 0>;
				strategy_temp_cool =		<11000 4455 2000 0 0
								11000 4455 1500 0 0
								11000 4465 1000 1 0>;
				strategy_temp_little_cool =	<11000 4460 2000 0 0
								11000 4460 1500 0 0
								11000 4470 1000 1 0>;
				strategy_temp_normal_low =	<11000 4460 2000 0 0
								11000 4460 1500 0 0
								11000 4470 1000 1 0>;
				strategy_temp_normal_high =	<11000 4460 2000 0 0
								11000 4460 1500 0 0
								11000 4470 1000 1 0>;
				strategy_temp_warm =		<11000 4130 1000 1 0>;
			};
			strategy_soc_range_high { /* ui_soc: 86%~90% */
				strategy_temp_little_cold =	<11000 4455 1500 0 0
								11000 4465 1000 1 0>;
				strategy_temp_cool =		<11000 4455 1500 0 0
								11000 4465 1000 1 0>;
				strategy_temp_little_cool =	<11000 4460 1500 0 0
								11000 4470 1000 1 0>;
				strategy_temp_normal_low =	<11000 4460 1500 0 0
								11000 4470 1000 1 0>;
				strategy_temp_normal_high =	<11000 4460 1500 0 0
								11000 4470 1000 1 0>;
				strategy_temp_warm =		<11000 4130 1000 1 0>;
			};
		};

		ufcs_charge_oplus_strategy {
			oplus,temp_type = <OPLUS_STRATEGY_USE_SHELL_TEMP>;
			oplus,soc_range = <0 20 35 50 75 85 90>;
			oplus,temp_range = <0 50 120 160 350 440 530>;
			strategy_soc_range_min {
				strategy_temp_little_cold =	<11000 4475 2500 0 0
								11000 4475 2000 0 0
								11000 4475 1500 0 0
								11000 4485 1000 1 0>;
				strategy_temp_cool =		<11000 4475 3000 0 0
								11000 4475 2500 0 0
								11000 4475 2000 0 0
								11000 4475 1500 0 0
								11000 4485 1000 1 0>;
				strategy_temp_little_cool =	<11000 4490 3000 0 0
								11000 4490 2500 0 0
								11000 4490 2000 0 0
								11000 4490 1500 0 0
								11000 4500 1000 1 0>;
				strategy_temp_normal_low =	<11000 4490 3000 0 0
								11000 4490 2500 0 0
								11000 4490 2000 0 0
								11000 4490 1500 0 0
								11000 4500 1000 1 0>;
				strategy_temp_normal_high =	<11000 4490 3000 0 0
								11000 4490 2500 0 0
								11000 4490 2000 0 0
								11000 4490 1500 0 0
								11000 4500 1000 1 0>;
				strategy_temp_warm =		<11000 4130 1000 1 0>;
			};
			strategy_soc_range_low {
				strategy_temp_little_cold =	<11000 4475 2500 0 0
								11000 4475 2000 0 0
								11000 4475 1500 0 0
								11000 4485 1000 1 0>;
				strategy_temp_cool =		<11000 4475 3000 0 0
								11000 4475 2500 0 0
								11000 4475 2000 0 0
								11000 4475 1500 0 0
								11000 4485 1000 1 0>;
				strategy_temp_little_cool =	<11000 4490 3000 0 0
								11000 4490 2500 0 0
								11000 4490 2000 0 0
								11000 4490 1500 0 0
								11000 4500 1000 1 0>;
				strategy_temp_normal_low =	<11000 4490 3000 0 0
								11000 4490 2500 0 0
								11000 4490 2000 0 0
								11000 4490 1500 0 0
								11000 4500 1000 1 0>;
				strategy_temp_normal_high =	<11000 4490 3000 0 0
								11000 4490 2500 0 0
								11000 4490 2000 0 0
								11000 4490 1500 0 0
								11000 4500 1000 1 0>;
				strategy_temp_warm =		<11000 4130 1000 1 0>;
			};
			strategy_soc_range_mid_low {
				strategy_temp_little_cold =	<11000 4475 2500 0 0
								11000 4475 2000 0 0
								11000 4475 1500 0 0
								11000 4485 1000 1 0>;
				strategy_temp_cool =		<11000 4475 3000 0 0
								11000 4475 2500 0 0
								11000 4475 2000 0 0
								11000 4475 1500 0 0
								11000 4485 1000 1 0>;
				strategy_temp_little_cool =	<11000 4490 3000 0 0
								11000 4490 2500 0 0
								11000 4490 2000 0 0
								11000 4490 1500 0 0
								11000 4500 1000 1 0>;
				strategy_temp_normal_low =	<11000 4490 3000 0 0
								11000 4490 2500 0 0
								11000 4490 2000 0 0
								11000 4490 1500 0 0
								11000 4500 1000 1 0>;
				strategy_temp_normal_high =	<11000 4490 3000 0 0
								11000 4490 2500 0 0
								11000 4490 2000 0 0
								11000 4490 1500 0 0
								11000 4500 1000 1 0>;
				strategy_temp_warm =		<11000 4130 1000 1 0>;
			};
			strategy_soc_range_mid {
				strategy_temp_little_cold =	<11000 4475 2500 0 0
								11000 4475 2000 0 0
								11000 4475 1500 0 0
								11000 4485 1000 1 0>;
				strategy_temp_cool =		<11000 4475 3000 0 0
								11000 4475 2500 0 0
								11000 4475 2000 0 0
								11000 4475 1500 0 0
								11000 4485 1000 1 0>;
				strategy_temp_little_cool =	<11000 4490 3000 0 0
								11000 4490 2500 0 0
								11000 4490 2000 0 0
								11000 4490 1500 0 0
								11000 4500 1000 1 0>;
				strategy_temp_normal_low =	<11000 4490 3000 0 0
								11000 4490 2500 0 0
								11000 4490 2000 0 0
								11000 4490 1500 0 0
								11000 4500 1000 1 0>;
				strategy_temp_normal_high =	<11000 4490 3000 0 0
								11000 4490 2500 0 0
								11000 4490 2000 0 0
								11000 4490 1500 0 0
								11000 4500 1000 1 0>;
				strategy_temp_warm =		<11000 4130 1000 1 0>;
			};
			strategy_soc_range_mid_high {
				strategy_temp_little_cold =	<11000 4475 2000 0 0
								11000 4475 1500 0 0
								11000 4485 1000 1 0>;
				strategy_temp_cool =		<11000 4475 2000 0 0
								11000 4475 1500 0 0
								11000 4485 1000 1 0>;
				strategy_temp_little_cool =	<11000 4490 2000 0 0
								11000 4490 1500 0 0
								11000 4500 1000 1 0>;
				strategy_temp_normal_low =	<11000 4490 2000 0 0
								11000 4490 1500 0 0
								11000 4500 1000 1 0>;
				strategy_temp_normal_high =	<11000 4490 2000 0 0
								11000 4490 1500 0 0
								11000 4500 1000 1 0>;
				strategy_temp_warm =		<11000 4130 1000 1 0>;
			};
			strategy_soc_range_high {
				strategy_temp_little_cold =	<11000 4475 1500 0 0
								11000 4485 1000 1 0>;
				strategy_temp_cool =		<11000 4475 1500 0 0
								11000 4485 1000 1 0>;
				strategy_temp_little_cool =	<11000 4490 1500 0 0
								11000 4500 1000 1 0>;
				strategy_temp_normal_low =	<11000 4490 1500 0 0
								11000 4500 1000 1 0>;
				strategy_temp_normal_high =	<11000 4490 1500 0 0
								11000 4500 1000 1 0>;
				strategy_temp_warm =		<11000 4130 1000 1 0>;
			};
		};

		oplus,impedance_node {
			ufcs_input_impedance: ufcs_input_impedance {
				node_name = "ufcs_input";
				default_impedance_mohm = <0>;
				default_curr_ma = <3000>;
				current_drop_table = <
					250  4000
					340  3000
					380  2000
					480 0
				>;
			};
		};
	};

	oplus_virtual_dpdm_switch: oplus,virtual_dpdm_switch {
		compatible = "oplus,virtual_dpdm_switch";

		oplus,ic_type = <OPLUS_CHG_IC_MISC>;
		oplus,ic_index = <0>;

		oplus,switch_ctrl-gpio = <&pio 134 0x00>;
		oplus,dpdm_switch1-gpio = <&pio 115 0x00>;

		pinctrl-names = "switch_ctrl_ap", "switch_ctrl_vooc", "switch_ctrl_ufcs",
						"dpdm_switch_ap", "dpdm_switch_vooc", "dpdm_switch_ufcs";
		pinctrl-0 = <&switch_ctrl_ap>;
		pinctrl-1 = <&switch_ctrl_vooc>;
		pinctrl-2 = <&switch_ctrl_ufcs>;
		pinctrl-3 = <&dpdm_switch_ap>;
		pinctrl-4 = <&dpdm_switch_vooc>;
		pinctrl-5 = <&dpdm_switch_ufcs>;
	};

	oplus_smart_charge: oplus,smart_charge {
		compatible = "oplus,smart_charge";
		oplus,quick_mode_gain_support;
	};
};

&soc {
	oplus_ufcs_impedance_check: oplus,ufcs_impedance_check {
		compatible = "oplus,impedance_check";

		oplus,impedance_unit {
			oplus_ufcs_impedance_unit: oplus,ufcs_impedance_unit {
				uint_name = "ufcs";
				default_curr_ma = <3000>;
				impedance_node = <&ufcs_input_impedance>;
			};
		};
	};
};

&i2c12 {
	status = "okay";
	clock-frequency = <400000>;
	pinctrl-names = "i2c-state", "output-low-state";
	pinctrl-0 = <&i2c12_i2c_state>;
	pinctrl-1 = <&i2c12_output_low_state>;
	mediatek,request-cpu-qos;
	oplus_sc8547a: oplus,sc8547a@6F {
		status = "okay";
		compatible = "oplus,sc8547a";
		reg = <0x6F>;

		oplus,use_vooc_phy;
		oplus,use_ufcs_phy;
		oplus,vac_support;
		oplus_spec,irq_gpio = <&pio 40 0x00>;
		interrupt-parent = <&pio>;
		interrupts = <9 0>;

		pinctrl-names = "charging_inter_active", "charging_inter_sleep";
		pinctrl-0 = <&charging_inter_active>;
		pinctrl-1 = <&charging_inter_sleep>;

		oplus,ic_type = <OPLUS_CHG_IC_VPHY>;
		oplus,ic_index = <0>;
		oplus,vooc-version = <VOOC_VERSION_5_0>;

		ocp_reg = <0xb>;
		ovp_reg = <0x36>;
		oplus_spec,voocphy_dual_cp_support;
		oplus_spec,slave_cp_enable_thr = <1400>;		//2000-100mA
		oplus_spec,slave_cp_disable_thr_high = <1100>;	//1500+100mA
		oplus_spec,voocphy_current_default = <61>;

		oplus_spec,svooc_cool_down_current_limit = <122 20 20 24 30 34 40 44 50 54 60 64 70 74>;
		oplus_spec,vooc_cool_down_current_limit = <61 20 20 24 30 34 40 44 50 54 60 64 70 74>;

		oplus_spec,vooc_multistep_initial_batt_temp = <1000>;
		oplus_spec,vooc_little_cool_temp = <160>;
		oplus_spec,vooc_cool_temp = <120>;
		oplus_spec,vooc_little_cold_temp = <50>;
		oplus_spec,vooc_normal_low_temp = <350>;
		oplus_spec,vooc_strategy_normal_current = <122>;
		oplus_spec,vooc_normal_to_little_cool_current = <100>;
		oplus_spec,vooc_over_high_temp = <510>;
		oplus_spec,vooc_low_temp = <0>;

		oplus_spec,vooc_high_temp = <500>;
		oplus_spec,vooc_low_soc = <0>;
		oplus_spec,vooc_high_soc = <90>;
		oplus_spec,vooc_normal_high_temp = <440>;
		oplus_spec,vooc_warm_vol_thr = <4000>;
		oplus_spec,vooc_warm_soc_thr = <50>;

		oplus_spec,vooc_strategy1_batt_high_temp0 = <385>;
		oplus_spec,vooc_strategy1_batt_high_temp1 = <395>;
		oplus_spec,vooc_strategy1_batt_high_temp2 = <420>;
		oplus_spec,vooc_strategy1_batt_low_temp2 = <410>;
		oplus_spec,vooc_strategy1_batt_low_temp1 = <385>;
		oplus_spec,vooc_strategy1_batt_low_temp0 = <375>;

		oplus_spec,vooc_strategy1_high_current0 = <80>;
		oplus_spec,vooc_strategy1_high_current1 = <61>;
		oplus_spec,vooc_strategy1_high_current2 = <40>;
		oplus_spec,vooc_strategy1_low_current2 = <40>;
		oplus_spec,vooc_strategy1_low_current1 = <61>;
		oplus_spec,vooc_strategy1_low_current0 = <80>;

		oplus_spec,vooc_strategy1_high_current0_vooc = <59>;
		oplus_spec,vooc_strategy1_high_current1_vooc = <59>;
		oplus_spec,vooc_strategy1_high_current2_vooc = <40>;
		oplus_spec,vooc_strategy1_low_current2_vooc = <59>;
		oplus_spec,vooc_strategy1_low_current1_vooc = <59>;
		oplus_spec,vooc_strategy1_low_current0_vooc = <59>;
		oplus_spec,voocphy_freq_mincore = <1800000>;
		oplus_spec,voocphy_freq_midcore = <1918000>;
		oplus_spec,voocphy_freq_maxcore = <1918000>;
		oplus_spec,voocphy_current_change_timeout = <100>;
		oplus_spec,copycat_vooc_support;
		oplus_spec,copycat_vooc_accuracy_value = <100>;

		oplus_spec,voocphy_ibat_over_current = <13500>;
		oplus_spec,voocphy_svooc_cp_max_ibus = <3500>;
		oplus_spec,voocphy_vooc_cp_max_ibus = <3500>;
		oplus_spec,voocphy_cp_max_ibus = <3500>;

		oplus_spec,vooc_little_cold_full_voltage = <4485>;
		oplus_spec,vooc_cool_full_voltage = <4485>;
		oplus_spec,vooc_warm_full_voltage = <4130>;
		oplus_spec,vooc_1time_full_voltage = <4500>;
		oplus_spec,vooc_ntime_full_voltage = <4500>;
		oplus_spec,low_curr_full_t1 = <120>;
		oplus_spec,low_curr_full_t2 = <350>;
		oplus_spec,low_curr_full_t3 = <430>;
		oplus_spec,range1_low_curr_full = <1500 4490
						1400 4480
						1300 4470
						1200 4460
						1100 4450>;
		oplus_spec,range2_low_curr_full = <1600 4490
						1400 4480
						1300 4470
						1200 4460
						1100 4450>;

		svooc_batt_sys_curve = <0 1 0 1 0 0 0	// 4000mA
					1 1 1 1 0 0 0	// 4604mV
					0 0 1 1 0 1 0	// 2600mA
					1 1 1 1 0 0 0	// 4604mV
					0 0 0 1 0 1 1	// 1100mA
					1 1 1 1 0 0 0>;	// 4604mV

		vooc_batt_sys_curve =  <0 1 0 1 0 0 0	// 4000mA
					1 1 1 1 0 0 0	// 4604mV
					0 0 1 1 0 1 0	// 2600mA
					1 1 1 1 0 0 0	// 4604mV
					0 0 0 1 0 1 1	// 1100mA
					1 1 1 1 0 0 0>;	// 4604mV

		svooc_charge_strategy {
			strategy_soc_0_to_50 {/* 0 ~ 20 */
				strategy_temp_little_cold =	<4180 25 0 0 0
								 4475 20 0 0 0
								 4475 15 0 0 0
								 4485 10 1 0 0>;
				strategy_temp_cool =	<4180  40 0 0 0
								 4475 25 0 0 0
								 4475 20 0 0 0
								 4475 15 0 0 0
								 4485 10 1 0 0>;
				strategy_temp_little_cool =	<4180 50 0 1440 0
								 4400 30 0 0 0
								 4400 25 0 0 0
								 4490 20 0 0 0
								 4490 15 0 0 0
								 4500 10 1 0 0>;
				strategy_temp_normal_low =	<4250 61 0 840 0
								 4250 50 0 1440 0
								 4400 40 0 0 0
								 4490 30 0 0 0
								 4490 25 0 0 0
								 4490 20 0 0 0
								 4490 15 0 0 0
								 4500 10 1 0 0>;
				strategy_temp_normal_high =	<4230 50 0 1440 0
								 4400 40 0 0 0
								 4490 30 0 0 0
								 4490 25 0 0 0
								 4490 20 0 0 0
								 4490 15 0 0 0
								 4500 10 1 0 0>;
				strategy_temp_warm = <4130 20 1 0 0>;
			};

			strategy_soc_50_to_75 {/* 56 ~ 75 */
				strategy_temp_little_cold =	<4475 20 0 0 0
								 4475 15 0 0 0
								 4485 10 1 0 0>;
				strategy_temp_cool =	<4180 40 0 0 0
								 4475 25 0 0 0
								 4475 20 0 0 0
								 4475 15 0 0 0
								 4485 10 1 0 0>;
				strategy_temp_little_cool =	<4180 50 0 1440 0
								 4490 30 0 0 0
								 4490 25 0 0 0
								 4490 20 0 0 0
								 4490 15 0 0 0
								 4500 10 1 0 0>;
				strategy_temp_normal_low =	<4250 61 0 840 0
								 4250 50 0 1440 0
								 4400 40 0 0 0
								 4490 30 0 0 0
								 4490 25 0 0 0
								 4490 20 0 0 0
								 4490 15 0 0 0
								 4450 10 1 0 0>;
				strategy_temp_normal_high =	<4230 50 0 1440 0
								 4400 40 0 0 0
								 4490 30 0 0 0
								 4490 25 0 0 0
								 4490 20 0 0 0
								 4490 15 0 0 0
								 4500 10 1 0 0>;
				strategy_temp_warm = <4130 20 1 0 0>;
			};

			strategy_soc_75_to_85 { /* 76 ~ 85 */
				strategy_temp_little_cold =	<4475 20 0 0 0
								 4475 15 0 0 0
								 4485 10 1 0 0>;
				strategy_temp_cool =	<4475 25 0 0 0
                                                         4475 20 0 0 0
							 4475 15 0 0 0
							 4485 10 1 0 0>;
				strategy_temp_little_cool =	<4400 30 0 0 0
								 4400 25 0 0 0
								 4490 20 0 0 0
								 4490 15 0 0 0
								 4500 10 1 0 0>;
				strategy_temp_normal_low =	<4400 40 0 0 0
								 4490 30 0 0 0
								 4490 25 0 0 0
								 4490 20 0 0 0
								 4490 15 0 0 0
								 4500 10 1 0 0>;
				strategy_temp_normal_high =	<4400 40 0 0 0
								 4490 30 0 0 0
								 4490 25 0 0 0
								 4490 20 0 0 0
								 4490 15 0 0 0
								 4500 10 1 0 0>;
				strategy_temp_warm = <4130 20 1 0 0>;
			};

			strategy_soc_85_to_90 { /* 86 ~ 95 */
				strategy_temp_little_cold =	<4475 20 0 0 0
                                                                 4475 15 0 0 0
                                                                 4485 10 1 0 0>;
				strategy_temp_cool =	<4475 25 0 0 0
                                                         4475 20 0 0 0
                                                         4475 15 0 0 0
                                                         4485 10 1 0 0>;
				strategy_temp_little_cool =	<4470 20 0 0 0
								 4470 15 0 0 0
								 4500 10 1 0 0>;
				strategy_temp_normal_low =	<4490 30 0 0 0
								 4490 25 0 0 0
								 4490 20 0 0 0
								 4490 15 0 0 0
								 4500 10 1 0 0>;
				strategy_temp_normal_high =	<4490 30 0 0 0
								 4490 25 0 0 0
								 4490 20 0 0 0
								 4490 15 0 0 0
								 4500 10 1 0 0>;
				strategy_temp_warm = <4130 20 1 0 0>;
			};
		};

		vooc_charge_strategy {
			strategy_soc_0_to_50 {
				strategy_temp_little_cold =	<4420 28 0 0 0
								 4485 20 1 0 0>;
				strategy_temp_cool =	<4475 40 0 0 0
								 4475 30 0 0 0
								 4475 20 1 0 0>;
				strategy_temp_little_cool =	<4490 59 0 1800 0
								 4490 50 0 0 0
								 4490 40 0 0 0
								 4490 30 0 0 0
								 4500 20 1 0 0>;
				strategy_temp_normal_low =	<4490 59 0 1800 0
								 4490 50 0 0 0
								 4490 40 0 0 0
								 4490 30 0 0 0
								 4500 20 1 0 0>;
				strategy_temp_normal_high =	<4490 59 0 1800 0
								 4490 50 0 0 0
								 4490 40 0 0 0
								 4490 30 0 0 0
								 4500 20 1 0 0>;
				strategy_temp_warm = <4130 20 1 0 0>;
			};

			strategy_soc_50_to_75 {
				strategy_temp_little_cold =	<4430 20 1 0 0>;
				strategy_temp_cool =	<4420 30 0 0 0
								 4485 20 1 0 0>;
				strategy_temp_little_cool =	<4490 40 0 0 0
								 4490 30 0 0 0
								 4500 20 1 0 0>;
				strategy_temp_normal_low =	<4490 50 0 0 0
								 4490 40 0 0 0
								 4490 30 0 0 0
								 4500 20 1 0 0>;
				strategy_temp_normal_high =	<4490 50 0 0 0
								 4490 40 0 0 0
								 4490 30 0 0 0
								 4500 20 1 0 0>;
				strategy_temp_warm = <4130 20 1 0 0>;
			};

			strategy_soc_75_to_85 {
				strategy_temp_little_cold =	<4485 20 1 0 0>;
				strategy_temp_cool =	<4485 20 1 0 0>;
				strategy_temp_little_cool =	<4500 20 1 0 0>;
				strategy_temp_normal_low =	<4490 30 0 0 0
								4500 20 1 0 0>;
				strategy_temp_normal_high =	<4490 30 0 0 0
								4500 20 1 0 0>;
				strategy_temp_warm = <4130 20 1 0 0>;
			};

			strategy_soc_85_to_90 {
				strategy_temp_little_cold =	<4430 20 1 0 0>;
				strategy_temp_cool =	<4430 20 1 0 0>;
				strategy_temp_little_cool =	<4480 20 1 0 0>;
				strategy_temp_normal_low =	<4480 20 1 0 0>;
				strategy_temp_normal_high =	<4480 20 1 0 0>;
				strategy_temp_warm = <4130 20 1 0 0>;
			};
		};
		oplus_sc8547_cp: oplus,sc8547_cp {
			oplus,ic_type = <OPLUS_CHG_IC_CP>;
			oplus,ic_index = <0>;
			oplus,ic_func_group = <&sc8547_cp_groups>;
		};
	};
};

&i2c0 {
	status = "okay";
	clock-frequency = <400000>;
	oplus_sc8547_slave: sc8547-charger-slave@6F{
		status = "okay";
		compatible = "slave_vphy_sc8547";
		reg = <0x6F>;

		ocp_reg = <0xb>;
		ovp_reg = <0x36>;/* vbat ovp 4.85v */
		oplus_sc8547_slave_cp: oplus,sc8547_slave_cp {
			oplus,ic_type = <OPLUS_CHG_IC_CP>;
			oplus,ic_index = <1>;
			oplus,ic_func_group = <&sc8547_cp_groups>;
		};
	};
};

#include "oplus-chg-dunhuang-pps.dtsi"

&i2c3 {
	status = "ok";
	pencil-wireless-charger@41 {
		status = "ok";
		compatible = "oplus,wls-charger-cps8601";
		reg = <0x41 0>;

		pinctrl-names = "wls_charge_int_active", "wls_charge_int_sleep", "wls_charge_int_default",
				"wls_sleep_active", "wls_sleep_sleep", "wls_sleep_default",
				"wls_scan_active", "wls_scan_sleep", "wls_scan_default",
				"wls_off_state_active", "wls_off_state_sleep", "wls_off_state_default",
				"wls_sw_en_active", "wls_sw_en_sleep", "wls_sw_en_default",
				"wls_boost_en_active", "wls_boost_en_sleep", "wls_boost_en_default";

		pinctrl-0 = <&wls_charge_int_active>;
		pinctrl-1 = <&wls_charge_int_sleep>;
		pinctrl-2 = <&wls_charge_int_default>;
		pinctrl-3 = <&wls_sleep_active>;
		pinctrl-4 = <&wls_sleep_sleep>;
		pinctrl-5 = <&wls_sleep_default>;
		pinctrl-6 = <&wls_scan_active>;
		pinctrl-7 = <&wls_scan_sleep>;
		pinctrl-8 = <&wls_scan_default>;
		pinctrl-9 = <&wls_off_state_active>;
		pinctrl-10 = <&wls_off_state_sleep>;
		pinctrl-11 = <&wls_off_state_default>;
		pinctrl-12 = <&wls_sw_en_active>;
		pinctrl-13 = <&wls_sw_en_sleep>;
		pinctrl-14 = <&wls_sw_en_default>;
		pinctrl-15 = <&wls_boost_en_active>;
		pinctrl-16 = <&wls_boost_en_sleep>;
		pinctrl-17 = <&wls_boost_en_default>;

		qcom,cps_wls_int-gpio = <&pio 29 0x00>;//WL_INT
		qcom,wls_sleep-gpio = <&pio 18 0x00>;//WL_AP_WAKEUP
		qcom,wls_scan-gpio = <&pio 46 0x00>;//WL_AP_SCAN
		qcom,wls_off_state-gpio = <&pio 26 0x00>;//WL_EN
		qcom,wls_sw_en-gpio = <&pio 127 0x00>;//BOOST_EN1
		qcom,wls_boost_en-gpio = <&pio 20 0x00>;//BOOST_EN2

		qcom,ocp_threshold = <500>;
		qcom,ovp_threshold = <12000>;
		qcom,lvp_threshold = <4000>;
		qcom,pcop_threshold1 = <700>;
		qcom,pcop_threshold2 = <500>;
		qcom,fod_threshold = <400>;
		rx,soc_threshold = <90>;
		//qcom,pen_is_supply_by_hboost = <0>;
		//qcom,hboost_default_volt_mv = <5800>;
	};
};

&pio {
	wls_sw_en_active: wls_sw_en_active {
		pins_cmd_dat {
			pinmux = <PINMUX_GPIO127__FUNC_GPIO127>;
			bias-pull-up;
			drive-strength = <2>;
		};
	};

	wls_sw_en_sleep: wls_sw_en_sleep {
		pins_cmd_dat {
			pinmux = <PINMUX_GPIO127__FUNC_GPIO127>;
			bias-pull-down;
			drive-strength = <2>;
		};
	};

	wls_sw_en_default: wls_sw_en_default {
		pins_cmd_dat {
			pinmux = <PINMUX_GPIO127__FUNC_GPIO127>;
			bias-pull-down;
			drive-strength = <2>;
		};
	};

	wls_charge_int_active: wls_charge_int_active {
		pins_cmd_dat {
			pinmux = <PINMUX_GPIO29__FUNC_GPIO29>;
			input-enable;
			bias-pull-up;
		};
	};

	wls_charge_int_sleep: wls_charge_int_sleep {
		pins_cmd_dat {
			pinmux = <PINMUX_GPIO29__FUNC_GPIO29>;
			input-enable;
			bias-pull-down;
		};
	};

	wls_charge_int_default: wls_charge_int_default {
		pins_cmd_dat {
			pinmux = <PINMUX_GPIO29__FUNC_GPIO29>;
			input-enable;
			bias-pull-up;
		};
	};

	wls_boost_en_active: wls_boost_en_active {
		pins_cmd_dat {
			pinmux = <PINMUX_GPIO20__FUNC_GPIO20>;
			bias-pull-up;
			drive-strength = <2>;
		};
	};

	wls_boost_en_sleep: wls_boost_en_sleep {
		pins_cmd_dat {
			pinmux = <PINMUX_GPIO20__FUNC_GPIO20>;
			bias-pull-down;
			drive-strength = <2>;
		};
	};

	wls_boost_en_default: wls_boost_en_default {
		pins_cmd_dat {
			pinmux = <PINMUX_GPIO20__FUNC_GPIO20>;
			bias-pull-down;
			drive-strength = <2>;
		};
	};

	wls_sleep_active: wls_sleep_active {
		pins_cmd_dat {
			pinmux = <PINMUX_GPIO18__FUNC_GPIO18>;
			bias-pull-up;
			drive-strength = <2>;
		};
	};

	wls_sleep_sleep: wls_sleep_sleep {
		pins_cmd_dat {
			pinmux = <PINMUX_GPIO18__FUNC_GPIO18>;
			bias-pull-down;
			drive-strength = <2>;
		};
	};

	wls_sleep_default: wls_sleep_default {
		pins_cmd_dat {
			pinmux = <PINMUX_GPIO18__FUNC_GPIO18>;
			bias-pull-down;
			drive-strength = <2>;
		};
	};

	wls_scan_active: wls_scan_active {
		pins_cmd_dat {
			pinmux = <PINMUX_GPIO46__FUNC_GPIO46>;
			bias-pull-up;
			drive-strength = <2>;
		};
	};

	wls_scan_sleep: wls_scan_sleep {
		pins_cmd_dat {
			pinmux = <PINMUX_GPIO46__FUNC_GPIO46>;
			bias-pull-down;
			drive-strength = <2>;
		};
	};

	wls_scan_default: wls_scan_default {
		pins_cmd_dat {
			pinmux = <PINMUX_GPIO46__FUNC_GPIO46>;
			bias-pull-up;
			drive-strength = <2>;
		};
	};

	wls_off_state_active: wls_off_state_active {
		pins_cmd_dat {
			pinmux = <PINMUX_GPIO26__FUNC_GPIO26>;
			bias-pull-up;
			drive-strength = <2>;
		};
	};

	wls_off_state_sleep: wls_off_state_sleep {
		pins_cmd_dat {
			pinmux = <PINMUX_GPIO26__FUNC_GPIO26>;
			bias-pull-down;
			drive-strength = <2>;
		};
	};

	wls_off_state_default: wls_off_state_default {
		pins_cmd_dat {
			pinmux = <PINMUX_GPIO26__FUNC_GPIO26>;
			bias-pull-up;
			drive-strength = <2>;
		};
	};
};

/* for pd common charger */
&ssusb {
		usb-psy-name = "mtk-master-charger";
		typec-name = "rt-pd-manager";
		typec-port-name = "port0";
};

&i2c5 {
		mediatek,fifo-use-polling;
		mediatek,request-cpu-qos;
};
